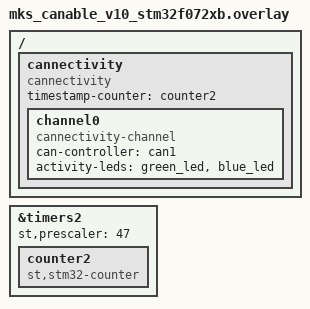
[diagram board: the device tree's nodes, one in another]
/*
 * SPDX-FileCopyrightText: Copyright (c) 2026 Navimatix GmbH
 * SPDX-FileCopyrightText: Copyright (c) 2026 TiaC Systems
 *
 * SPDX-License-Identifier: Apache-2.0
 */

#include <zephyr/dt-bindings/gpio/gpio.h>
#include "../app.overlay"

/ {
	cannectivity: cannectivity {
		compatible = "cannectivity";
		timestamp-counter = <&counter2>;

		channel0 {
			compatible = "cannectivity-channel";
			can-controller = <&can1>;
			activity-leds = <&green_led &blue_led>;
		};
	};
};

&timers2 {
	status = "okay";
	st,prescaler = <47>;

	counter2: counter2 {
		compatible = "st,stm32-counter";
		status = "okay";
	};
};
